# emif4 register map
Vendor: Texas Instruments
Peripheral module from a debugger description file (folder am335x).
Registers are 32-bit, access per field, no defined reset value unless marked. A register's access mark holds for its fields unless they carry their own. Offsets are as the file gives them; lines under a group give offsets from that group; [hi:lo] are bit positions; {n}, {i} and the like mark numbered series; 'fields as' and 'values as' point back to an identical list; <NAME> marks a mode.

## EMIF4D
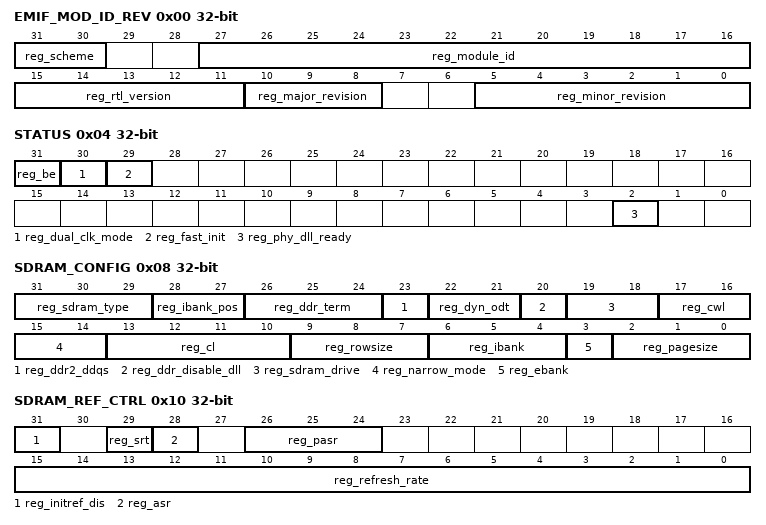
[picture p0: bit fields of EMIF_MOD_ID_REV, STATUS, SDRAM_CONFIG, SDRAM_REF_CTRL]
0x00 EMIF_MOD_ID_REV ro
  [31:30] reg_scheme — Used to distinguish between old and current schemes.
  [27:16] reg_module_id — EMIF module ID.
  [15:11] reg_rtl_version — RTL Version.
  [10:8] reg_major_revision — Major Revision.
  [5:0] reg_minor_revision — Minor Revision.
0x04 STATUS ro
  [31] reg_be — Big Endian. Reflects the value on the config_big_endian port that defines whether the EMIF is in big or little endian mode. 0 = Little endian. 1 = Big endian.
  [30] reg_dual_clk_mode — Dual Clock mode. Reflects the value on the config_dual_clk_mode port that defines whether the ocp_clk and m_clk are asynchronous. 0 = ocp_clk = m_clk. 1 = Asynchronous ocp_clk and m_clk.
  [29] reg_fast_init — Fast Init. Reflects the value on the config_fast_init port that defines whether the EMIF fast initialization mode has been enabled. 0 = Fast init disabled. 1 = Fast init enabled.
  [2] reg_phy_dll_ready — DDR PHY Ready. Reflects the value on the phy_ready port (active high) that defines whether the DDR PHY is ready for normal operation.
0x08 SDRAM_CONFIG rw
  [31:29] reg_sdram_type — SDRAM Type selection. Set to 0 for DDR1, set to 1 for LPDDR1, set to 2 for DDR2, set to 3 for DDR3. All other values are reserved.
  [28:27] reg_ibank_pos — Internal bank position. Set to 0 to assign internal bank address bits from lower OCP address bits, as shown in the tables for OCP Address to DDR2/3/mDDR Address Mapping. Set to 1, 2, or 3 to assign internal bank address bits from higher OCP address, as shown in the tables for OCP Address to DDR2/3/mDDR Address Mapping.
  [26:24] reg_ddr_term — DDR2 and DDR3 termination resistor value. Set to 0 to disable termination. For DDR2, set to 1 for 75 ohm, set to 2 for 150 ohm, and set to 3 for 50 ohm. For DDR3, set to 1 for RZQ/4, set to 2 for RZQ/2, set to 3 for RZQ/6, set to 4 for RZQ/12, and set to 5 for RZQ/8. All other values are reserved.
  [23] reg_ddr2_ddqs — DDR2 differential DQS enable. Set to 0 for single ended DQS. Set to 1 for differential DQS.
  [22:21] reg_dyn_odt — DDR3 Dynamic ODT. Set to 0 to turn off dynamic ODT. Set to 1 for RZQ/4 and set to 2 for RZQ/2. All other values are reserved.
  [20] reg_ddr_disable_dll — Disable DLL select. Set to 1 to disable DLL inside SDRAM.
  [19:18] reg_sdram_drive — SDRAM drive strength. For DDR1/DDR2, set to 0 for normal, and set to 1 for weak drive strength. For DDR3, set to 0 for RZQ/6 and set to 1 for RZQ/7. For LPDDR1, set to 0 for full, set to 1 for 1/2, set to 2 for 1/4, and set to 3 for 1/8 drive strength. All other values are reserved.
  [17:16] reg_cwl — DDR3 CAS Write latency. Value of 0, 1, 2, and 3 (CAS write latency of 5, 6, 7, and 8) are supported. Use the lowest value supported for best performance. All other values are reserved.
  [15:14] reg_narrow_mode — SDRAM data bus width. Set to 0 for 32-bit and set to 1 for 16-bit. All other values are reserved.
  [13:10] reg_cl — CAS Latency. The value of this field defines the CAS latency to be used when accessing connected SDRAM devices. Value of 2, 3, 5, and 6 (CAS latency of 2, 3, 1.5, and 2.5) are supported for DDR1. Value of 2, 3, 4, and 5 (CAS latency of 2, 3, 4, and 5) are supported for DDR2. Value of 2, 4, 6, 8, 10, 12, and 14 (CAS latency of 5, 6, 7, 8, 9, 10, and 11) are supported for DDR3. Value of 2 and 3 (CAS latency of 2 and 3) are supported for LPDDR1. All other values are reserved.
  [9:7] reg_rowsize — Row Size. Defines the number of row address bits of connected SDRAM devices. Set to 0 for 9 row bits, set to 1 for 10 row bits, set to 2 for 11 row bits, set to 3 for 12 row bits, set to 4 for 13 row bits, set to 5 for 14 row bits, set to 6 for 15 row bits, and set to 7 for 16 row bits. This field is only used when reg_ibank_pos field in SDRAM Config register is set to 1, 2, or 3, or reg_ebank_pos field in SDRAM Config_2 register is set to 1.
  [6:4] reg_ibank — Internal Bank setup. Defines number of banks inside connected SDRAM devices. Set to 0 for 1 bank, set to 1 for 2 banks, set to 2 for 4 banks, and set to 3 for 8 banks. All other values are reserved.
  [3] reg_ebank — External chip select setup. Defines whether SDRAM accesses will use 1 or 2 chip select lines. Set to 0 to use pad_cs_o_n[0] only. All other values reserved.
  [2:0] reg_pagesize — Page Size. Defines the internal page size of connected SDRAM devices. Set to 0 for 256-word page (8 column bits), set to 1 for 512-word page (9 column bits), set to 2 for 1024-word page (10 column bits), and set to 3 for 2048-word page (11 column bits). All other values are reserved.
0x0C SDRAM_CONFIG_2
  [27] reg_ebank_pos rw — External bank position. Set to 0 to assign external bank address bits from lower OCP address, as shown in the tables for OCP Address to DDR2/3/mDDR Address Mapping. Set to 1 to assign external bank address bits from higher OCP address bits, as shown in the tables for OCP Address to DDR2/3/mDDR Address Mapping.
0x10 SDRAM_REF_CTRL
  [31] reg_initref_dis rw — Initialization and Refresh disable. When set to 1, EMIF will disable SDRAM initialization and refreshes, but will carry out SDRAM write/read transactions.
  [29] reg_srt rw — DDR3 Self Refresh temperature range. Set to 0 for normal operating temperature range and set to 1 for extended operating temperature range when the reg_asr field is set to 0. This bit must be set to 0 if the reg_asr field is set to 1. A write to this field will cause the EMIF to start the SDRAM initialization sequence.
  [28] reg_asr rw — DDR3 Auto Self Refresh enable. Set to 1 for auto Self Refresh enable. Set to 0 for manual Self Refresh reference indicated by the reg_srt field. A write to this field will cause the EMIF to start the SDRAM initialization sequence.
  [26:24] reg_pasr rw — Partial Array Self Refresh. These bits get loaded into the Extended Mode Register of an LPDDR1 or DDR3 during initialization. For LPDDR1, set to 0 for full array, set to 1 for 1/2 array, set to 2 for 1/4 array, set to 5 for 1/8 array, and set to 6 for 1/16 array to be refreshed. For DDR3, set to 0 for full array, set to 1 or 5 for 1/2 array, set to 2 or 6 for 1/4 array, set to 3 or 7 for 1/8 array, and set to 4 for 3/4 array to be refreshed. All other values are reserved. A write to this field will cause the EMIF to start the SDRAM initialization sequence.
  [15:0] reg_refresh_rate rw — Refresh Rate. Value in this field is used to define the rate at which connected SDRAM devices will be refreshed. SDRAM refresh rate = EMIF rate / reg_refresh_rate where EMIF rate is equal to m_clk rate. If reg_refresh_rate andlt (8*reg_t_rfc)+reg_t_rp+reg_t_rcd+20 then it will be loaded with (8*reg_t_rfc)+reg_t_rp+reg_t_rcd+20. This is done to avoid lock-up situations when illegal values are programmed.
0x14 SDRAM_REF_CTRL_SHDW
  [15:0] reg_refresh_rate_shdw rw — Shadow field for reg_refresh_rate. This field is loaded into reg_refresh_rate field in SDRAM Refresh Control register when SIdleAck is asserted. This register is not auto corrected when the value is invalid.
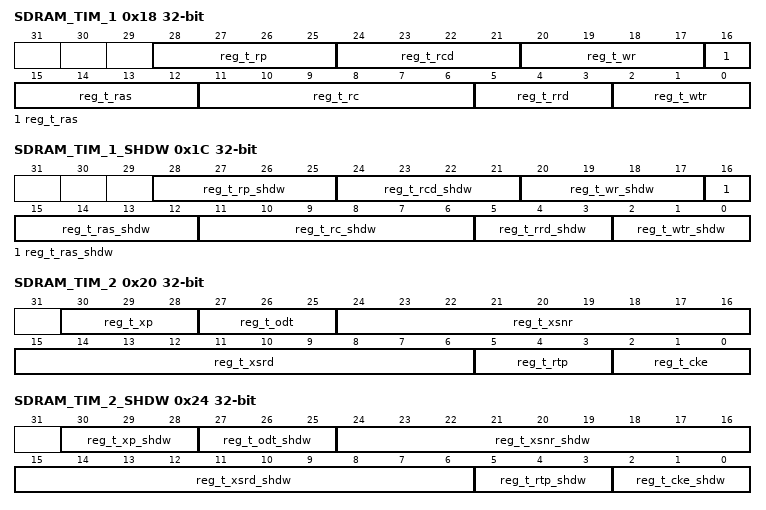
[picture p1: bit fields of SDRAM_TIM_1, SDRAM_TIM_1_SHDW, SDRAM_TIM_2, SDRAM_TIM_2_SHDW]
0x18 SDRAM_TIM_1
  [28:25] reg_t_rp rw — Minimum number of m_clk cycles from Precharge to Activate or Refresh, minus one.
  [24:21] reg_t_rcd rw — Minimum number of m_clk cycles from Activate to Read or Write, minus one.
  [20:17] reg_t_wr rw — Minimum number of m_clk cycles from last Write transfer to Pre-charge, minus one. The SDRAM initialization sequence will be started when the value of this field is changed from the previous value and the EMIF is in DDR2 mode.
  [16:12] reg_t_ras rw — Minimum number of m_clk cycles from Activate to Pre-charge, minus one. reg_t_ras >= reg_t_rcd.
  [11:6] reg_t_rc rw — Minimum number of m_clk cycles from Activate to Activate, minus one.
  [5:3] reg_t_rrd rw — Minimum number of m_clk cycles from Activate to Activate for a different bank, minus one. For an 8-bank DDR2, this field must be equal to ((((4*tRRD)+(2*tCK))/(4*tCK))-1).
  [2:0] reg_t_wtr rw — Minimum number of m_clk cycles from last Write to Read, minus one.
0x1C SDRAM_TIM_1_SHDW
  [28:25] reg_t_rp_shdw rw — Shadow field for reg_t_rp. This field is loaded into reg_t_rp field in SDRAM Timing 1 register when SIdleAck is asserted.
  [24:21] reg_t_rcd_shdw rw — Shadow field for reg_t_rcd. This field is loaded into reg_t_rcd field in SDRAM Timing 1 register when SIdleAck is asserted.
  [20:17] reg_t_wr_shdw rw — Shadow field for reg_t_wr. This field is loaded into reg_t_wr field in SDRAM Timing 1 register when SIdleAck is asserted. initialization sequence will be started when the value of this field is changed from the previous value and the EMIF is in DDR2 mode.
  [16:12] reg_t_ras_shdw rw — Shadow field for reg_t_ras. This field is loaded into reg_t_ras field in SDRAM Timing 1 register when SIdleAck is asserted.
  [11:6] reg_t_rc_shdw rw — Shadow field for reg_t_rc. This field is loaded into reg_t_rc field in SDRAM Timing 1 register when SIdleAck is asserted.
  [5:3] reg_t_rrd_shdw rw — Shadow field for reg_t_rrd. This field is loaded into reg_t_rrd field in SDRAM Timing 1 register when SIdleAck is asserted.
  [2:0] reg_t_wtr_shdw rw — Shadow field for reg_t_wtr. This field is loaded into reg_t_wtr field in SDRAM Timing 1 register when SIdleAck is asserted.
0x20 SDRAM_TIM_2
  [30:28] reg_t_xp rw — Minimum number of m_clk cycles from Powerdown exit to any command other than a Read command, minus one. For DDR2 and LPDDR1, this field must satisfy greater of tXP or tCKE.
  [27:25] reg_t_odt rw — Minimum number of m_clk cycles from ODT enable to write data driven for DDR2 and DDR3. reg_t_odt must be equal to tAOND.
  [24:16] reg_t_xsnr rw — Minimum number of m_clk cycles from Self-Refresh exit to any command other than a Read command, minus one.
  [15:6] reg_t_xsrd rw — Minimum number of m_clk cycles from Self-Refresh exit to a Read command, minus one.
  [5:3] reg_t_rtp rw — Minimum number of m_clk cycles from the last Read command to a Pre-charge command for DDR2, minus one.
  [2:0] reg_t_cke rw — Minimum number of m_clk cycles between pad_cke_o changes, minus one.
0x24 SDRAM_TIM_2_SHDW
  [30:28] reg_t_xp_shdw rw — Shadow field for reg_t_xp. This field is loaded into reg_t_xp field in SDRAM Timing 2 register when SIdleAck is asserted.
  [27:25] reg_t_odt_shdw rw — Shadow field for reg_t_odt. This field is loaded into reg_t_odt field in SDRAM Timing 2 register when SIdleAck is asserted.
  [24:16] reg_t_xsnr_shdw rw — Shadow field for reg_t_xsnr. This field is loaded into reg_t_xsnr field in SDRAM Timing 2 register when SIdleAck is asserted.
  [15:6] reg_t_xsrd_shdw rw — Shadow field for reg_t_xsrd. This field is loaded into reg_t_xsrd field in SDRAM Timing 2 register when SIdleAck is asserted.
  [5:3] reg_t_rtp_shdw rw — Shadow field for reg_t_rtp. This field is loaded into reg_t_rtp field in SDRAM Timing 2 register when SIdleAck is asserted.
  [2:0] reg_t_cke_shdw rw — Shadow field for reg_t_cke. This field is loaded into reg_t_cke field in SDRAM Timing 2 register when SIdleAck is asserted.
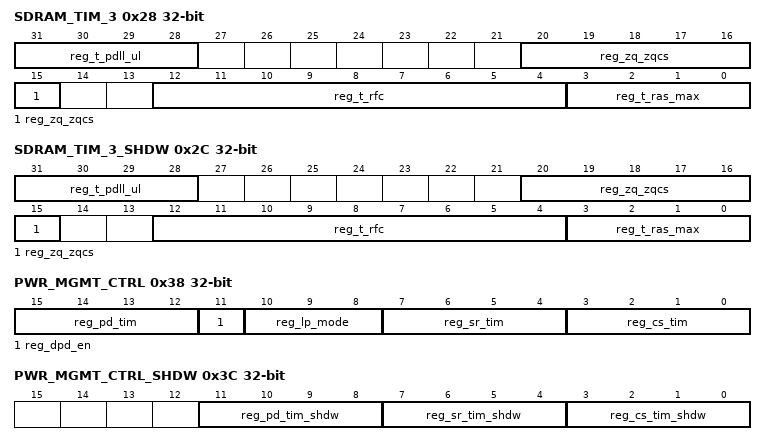
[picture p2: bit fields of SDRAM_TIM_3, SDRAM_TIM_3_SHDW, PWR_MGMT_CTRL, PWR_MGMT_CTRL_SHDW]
0x28 SDRAM_TIM_3
  [31:28] reg_t_pdll_ul rw — Minimum number of DDR clock cycles for PHY DLL to unlock. A value of N will be equal to N x 128 clocks.
  [20:15] reg_zq_zqcs rw — Number of DDR clock clock cycles for a ZQCS command, minus one.
  [12:4] reg_t_rfc rw — Minimum number of DDR clock cycles from Refresh or Load Mode to Refresh or Activate, minus one.
  [3:0] reg_t_ras_max rw — Maximum number of reg_refresh_rate intervals from Activate to Precharge command. This field must be equal to ((tRASmax / tREFI)-1) rounded down to the next lower integer. This field is only applicable for mDDR. This field must be programmed to 0xF for other SDRAM types.
0x2C SDRAM_TIM_3_SHDW
  fields as SDRAM_TIM_3
0x38 PWR_MGMT_CTRL
  [15:12] reg_pd_tim rw — Power Mangement timer for Power-Down. The EMIF will put the external SDRAM in Power-Down mode after the EMIF is idle for these number of m_clk cycles and if reg_lp_mode field is set to 4. Set to 0 to immediately enter Power-Down mode. Set to 1 for 16 clocks. Set to 2 for 32 clocks. Set to 3 for 64 clocks. Set to 4 for 128 clocks. Set to 5 for 256 clocks. Set to 6 for 512 clocks. Set to 7 for 1024 clocks. Set to 8 for 2048 clocks. Set to 9 for 4096 clocks. Set to 10 for 8192 clocks. Set to 11 for 16384 clocks. Set to 12 for 32768 clocks. Set to 13 for 65536 clocks. Set to 14 for 131072 clocks. Set to 15 for 262144 clocks. Note: After updating this field, at least one dummy read access to SDRAM is required for the new value to take affect.
  [11] reg_dpd_en rw — Deep Power Down enable. Set to 0 for normal operation. Set to 1 to enter deep power down mode. This mode will override the reg_lp_mode field setting.
  [10:8] reg_lp_mode rw — Automatic Power Management enable. Set to 1 for Clock Stop, set to 2 for Self Refresh, and set to 4 for Power-Down. All other values will disable automatic power management.
  [7:4] reg_sr_tim rw — Power Mangement timer for Self Refresh. The EMIF will put the external SDRAM in Self Refresh mode after the EMIF is idle for these number of m_clk cycles and if reg_lp_mode field is set to 2. Set to 0 to immediately enter Self Refresh mode. Set to 1 for 16 clocks. Set to 2 for 32 clocks. Set to 3 for 64 clocks. Set to 4 for 128 clocks. Set to 5 for 256 clocks. Set to 6 for 512 clocks. Set to 7 for 1024 clocks. Set to 8 for 2048 clocks. Set to 9 for 4096 clocks. Set to 10 for 8192 clocks. Set to 11 for 16384 clocks. Set to 12 for 32768 clocks. Set to 13 for 65536 clocks. Set to 14 for 131072 clocks. Set to 15 for 262144 clocks. Note: After updating this field, at least one dummy read access to SDRAM is required for the new value to take affect.
  [3:0] reg_cs_tim rw — Power Mangement timer for Clock Stop. The EMIF will put the external SDRAM in Clock Stop mode after the EMIF is idle for these number of m_clk cycles and if reg_lp_mode field is set to 1. Set to 0 to immediately enter Clock Stop mode. Set to 1 for 16 clocks. Set to 2 for 32 clocks. Set to 3 for 64 clocks. Set to 4 for 128 clocks. Set to 5 for 256 clocks. Set to 6 for 512 clocks. Set to 7 for 1024 clocks. Set to 8 for 2048 clocks. Set to 9 for 4096 clocks. Set to 10 for 8192 clocks. Set to 11 for 16384 clocks. Set to 12 for 32768 clocks. Set to 13 for 65536 clocks. Set to 14 for 131072 clocks. Set to 15 for 262144 clocks. Note: After updating this field, at least one dummy read access to SDRAM is required for the new value to take affect.
0x3C PWR_MGMT_CTRL_SHDW
  [11:8] reg_pd_tim_shdw rw — Shadow field for reg_pd_tim. This field is loaded into reg_pd_tim field in Power Management Control register when SIdleAck is asserted.
  [7:4] reg_sr_tim_shdw rw — Shadow field for reg_sr_tim. This field is loaded into reg_sr_tim field in Power Management Control register when SIdleAck is asserted.
  [3:0] reg_cs_tim_shdw rw — Shadow field for reg_cs_tim. This field is loaded into reg_cs_tim field in Power Management Control register when SIdleAck is asserted.
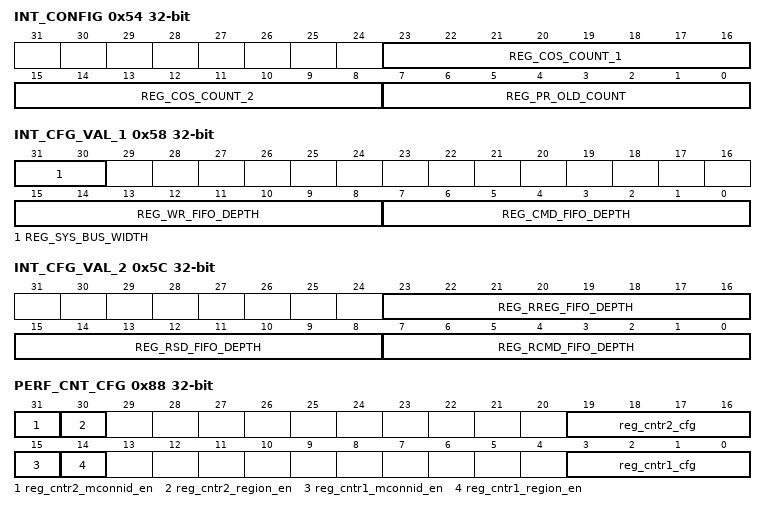
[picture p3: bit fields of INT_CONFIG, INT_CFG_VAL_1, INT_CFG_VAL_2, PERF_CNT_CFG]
0x54 INT_CONFIG access not given
  [23:16] REG_COS_COUNT_1 rw — Priority Raise Counter for class of service 1. Number of m_clk cycles after which the EMIF momentarily raises the priority of the class of service 1 commands in the Command FIFO. A value of N will be equal to N x 16 clocks.
  [15:8] REG_COS_COUNT_2 rw — Priority Raise Counter for class of service 2. Number of m_clk cycles after which the EMIF momentarily raises the priority of the class of service 2 commands in the Command FIFO. A value of N will be equal to N x 16 clocks.
  [7:0] REG_PR_OLD_COUNT — Priority Raise Old Counter. Number of m_clk cycles after which the EMIF momentarily raises the priority of the oldest command in the OCP Command FIFO. A value of N will be equal to N x 16 clocks.
0x58 INT_CFG_VAL_1 ro
  [31:30] REG_SYS_BUS_WIDTH — L3 OCP data bus width for a particular configuration. 0 = 32 bit wide. 1 = 64 bit wide. 2 = 128 bit wide. 3 = 256 bit wide.
  [15:8] REG_WR_FIFO_DEPTH — Write Data FIFO depth for a particular configuration.
  [7:0] REG_CMD_FIFO_DEPTH — Command FIFO depth for a particular configuration.
0x5C INT_CFG_VAL_2 ro
  [23:16] REG_RREG_FIFO_DEPTH — Register Read Data FIFO depth for a particular configuration.
  [15:8] REG_RSD_FIFO_DEPTH — SDRAM Read Data FIFO depth for a particular configuration.
  [7:0] REG_RCMD_FIFO_DEPTH — Read Command FIFO depth for a particular configuration.
0x80 PERF_CNT_1 ro
  [31:0] reg_counter1 — 32-bit counter that can be configured as specified in the Performance Counter Config Register and Performance Counter Master Region Select Register.
0x84 PERF_CNT_2 ro
  [31:0] reg_counter2 — 32-bit counter that can be configured as specified in the Performance Counter Config Register and Performance Counter Master Region Select Register.
0x88 PERF_CNT_CFG
  [31] reg_cntr2_mconnid_en rw — MConnID filter enable for Performance Counter 2 register.
  [30] reg_cntr2_region_en rw — Chip Select filter enable for Performance Counter 2 register.
  [19:16] reg_cntr2_cfg rw — Filter configuration for Performance Counter 2. Refer to table for details.
  [15] reg_cntr1_mconnid_en rw — MConnID filter enable for Performance Counter 1 register.
  [14] reg_cntr1_region_en rw — Chip Select filter enable for Performance Counter 1 register.
  [3:0] reg_cntr1_cfg rw — Filter configuration for Performance Counter 1. Refer to table for details.
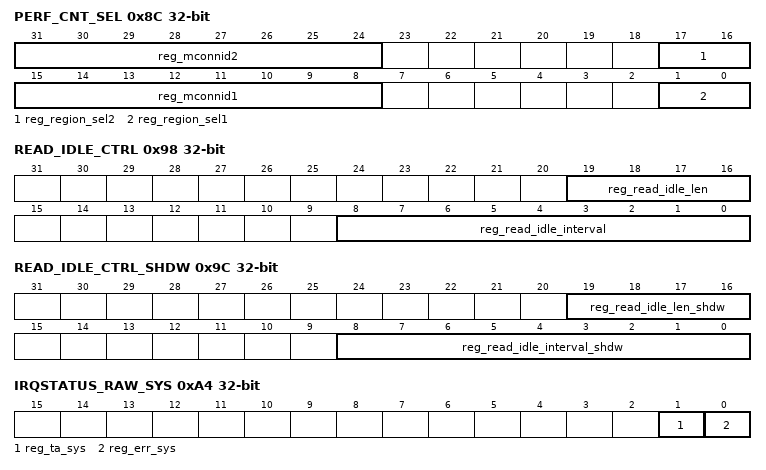
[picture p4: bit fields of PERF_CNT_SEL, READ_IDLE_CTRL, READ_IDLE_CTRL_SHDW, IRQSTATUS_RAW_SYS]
0x8C PERF_CNT_SEL
  [31:24] reg_mconnid2 rw — MConnID for Performance Counter 2 register.
  [17:16] reg_region_sel2 rw — MAddrSpace for Performance Counter 2 register.
  [15:8] reg_mconnid1 rw — MConnID for Performance Counter 1 register.
  [1:0] reg_region_sel1 rw — MAddrSpace for Performance Counter 1 register.
0x90 PERF_CNT_TIM ro
  [31:0] reg_total_time — 32-bit counter that continuously counts number for m_clk cycles elapsed after EMIF is brought out of reset.
0x98 READ_IDLE_CTRL
  [19:16] reg_read_idle_len rw — The Read Idle Length field determines the minimum size (reg_read_idle_len-1 clock cycles) of Read Idle window for the read idle detection as well as the force read idle time.
  [8:0] reg_read_idle_interval rw — The Read Idle Interval field determines the maximum interval ((reg_read_idle_interval-1)*64 clock cycles) between read idle detections or force. A value of zero disables the read idle function.
0x9C READ_IDLE_CTRL_SHDW
  [19:16] reg_read_idle_len_shdw rw — Shadow field for reg_read_idle_len. This field is loaded into reg_read_idle_len field in Read Idle Control register when SIdleAck is asserted
  [8:0] reg_read_idle_interval_shdw rw — Shadow field for reg_read_idle_interval. This field is loaded into reg_read_idle_interval field in Read Idle Control register when SIdleAck is asserted.
0xA4 IRQSTATUS_RAW_SYS
  [1] reg_ta_sys rw — Raw status of system OCP interrupt. Write 1 to set the (raw) status, mostly for debug. Writing a 0 has no effect.
  [0] reg_err_sys rw — Raw status of system OCP interrupt. Write 1 to set the (raw) status, mostly for debug. Writing a 0 has no effect.
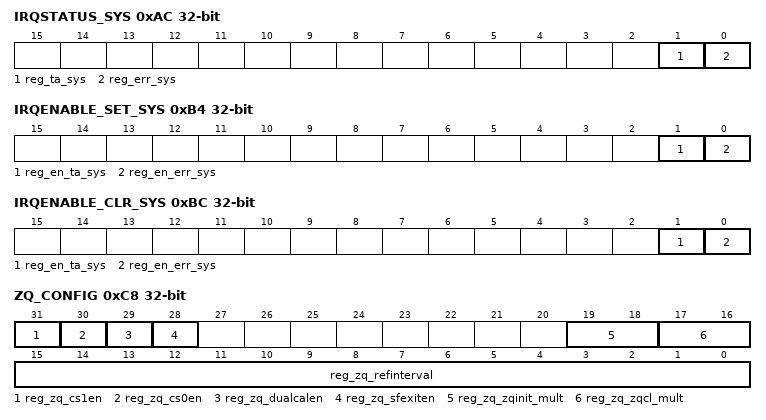
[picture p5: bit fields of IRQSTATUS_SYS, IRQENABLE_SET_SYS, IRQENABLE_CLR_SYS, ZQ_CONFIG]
0xAC IRQSTATUS_SYS
  [1] reg_ta_sys rw — Enabled status of system OCP interrupt. Write 1 to clear the status after interrupt has been serviced (raw status gets cleared, i.e. even if not enabled). Writing a 0 has no effect.
  [0] reg_err_sys rw — Enabled status of system OCP interrupt. Write 1 to clear the status after interrupt has been serviced (raw status gets cleared, i.e. even if not enabled). Writing a 0 has no effect.
0xB4 IRQENABLE_SET_SYS
  [1] reg_en_ta_sys rw — Enable set for system OCP interrupt. Writing a 1 will enable the interrupt, and set this bit as well as the corresponding Interrupt Enable Clear Register. Writing a 0 has no effect.
  [0] reg_en_err_sys rw — Enable set for system OCP interrupt. Writing a 1 will enable the interrupt, and set this bit as well as the corresponding Interrupt Enable Clear Register. Writing a 0 has no effect.
0xBC IRQENABLE_CLR_SYS
  [1] reg_en_ta_sys rw — Enable clear for system OCP interrupt. Writing a 1 will disable the interrupt, and clear this bit as well as the corresponding Interrupt Enable Set Register. Writing a 0 has no effect.
  [0] reg_en_err_sys rw — Enable clear for system OCP interrupt. Writing a 1 will disable the interrupt, and clear this bit as well as the corresponding Interrupt Enable Set Register. Writing a 0 has no effect.
0xC8 ZQ_CONFIG
  [31] reg_zq_cs1en rw — Writing a 1 enables ZQ calibration for CS1.
  [30] reg_zq_cs0en rw — Writing a 1 enables ZQ calibration for CS0.
  [29] reg_zq_dualcalen rw — ZQ Dual Calibration enable. Allows both ranks to be ZQ calibrated simultaneously. Setting this bit requires both chip selects to have a seerate calibration resistor per device.
  [28] reg_zq_sfexiten rw — ZQCL on Self Refresh, Active Power-Down, and Precharge Power-Down exit enable. Writing a 1 enables the issuing of ZQCL on Self-Refresh, Active Power-Down, and Precharge Power-Down exit.
  [19:18] reg_zq_zqinit_mult rw — Indicates the number of ZQCL intervals that make up a ZQINIT interval, minus one.
  [17:16] reg_zq_zqcl_mult rw — Indicates the number of ZQCS intervals that make up a ZQCL interval, minus one. ZQCS interval is defined by reg_zq_zqcs in SDRAM Timing 3 Register.
  [15:0] reg_zq_refinterval rw — Number of refresh periods between ZQCS commans. This field supports between one refresh period to 256 ms between ZQCS calibration commands. Refresh period is defined by reg_refresh_rate in SDRAM Refresh Control register.
0xD4 RDWR_LVL_RMP_WIN ro
  [12:0] REG_RDWRLVLINC_RMP_WIN — Incremental leveling ramp window in number of refresh periods. The value programmed is minus one the required value. Refresh period is defined by reg_refresh_rate in SDRAM Refresh Control register.
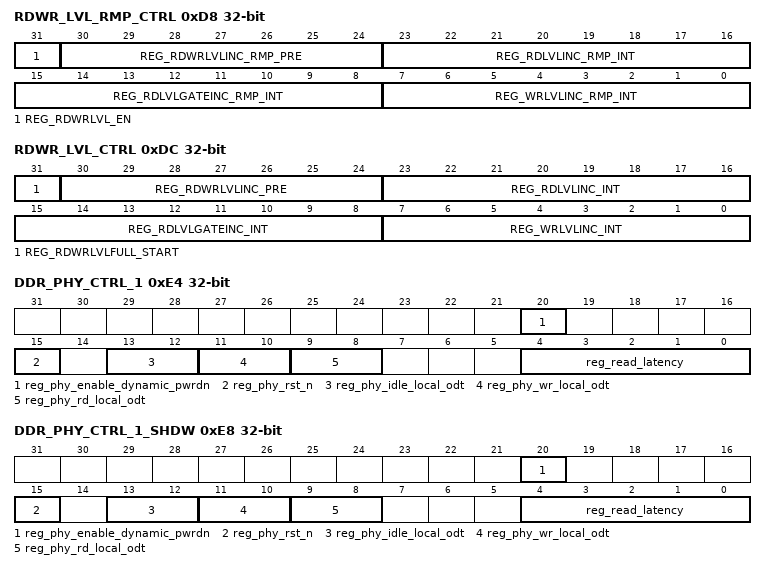
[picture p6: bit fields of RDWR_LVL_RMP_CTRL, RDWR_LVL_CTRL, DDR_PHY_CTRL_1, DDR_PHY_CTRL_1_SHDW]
0xD8 RDWR_LVL_RMP_CTRL access not given
  [31] REG_RDWRLVL_EN rw — Read-Write Leveling enable. Set 1 to enable leveling. Set 0 to disable leveling.
  [30:24] REG_RDWRLVLINC_RMP_PRE — Incremental leveling pre-scalar in number of refresh periods during ramp window. The value programmed is minus one the required value. Refresh period is defined by reg_refresh_rate in SDRAM Refresh Control register.
  [23:16] REG_RDLVLINC_RMP_INT rw — Incremental read data eye training interval during ramp window. Number of reg_rdwrlvlinc_rmp_pre intervals between incremental read data eye training. A value of 0 will disable incremental read data eye training during ramp window.
  [15:8] REG_RDLVLGATEINC_RMP_INT rw — Incremental read DQS gate training interval during ramp window. Number of reg_rdwrlvlinc_rmp_pre intervals between incremental read DQS gate training. A value of 0 will disable incremental read DQS gate training during ramp window.
  [7:0] REG_WRLVLINC_RMP_INT — Incremental write leveling interval during ramp window. Number of reg_rdwrlvlinc_rmp_pre intervals between incremental write leveling. A value of 0 will disable incremental write leveling during ramp window.
0xDC RDWR_LVL_CTRL access not given — Read-Write Leveling Control Register
  [31] REG_RDWRLVLFULL_START rw — Full leveling trigger. Writing a 1 to this field triggers full read and write leveling. This bit will self-clear to 0.
  [30:24] REG_RDWRLVLINC_PRE — Incremental leveling pre-scalar in number of refresh periods. The value programmed is minus one the required value. Refresh period is defined by reg_refresh_rate in SDRAM Refresh Control register.
  [23:16] REG_RDLVLINC_INT rw — Incremental read data eye training interval. Number of reg_rdwrlvlinc_pre intervals between incremental read data eye training. A value of 0 will disable incremental read data eye training.
  [15:8] REG_RDLVLGATEINC_INT rw — Incremental read DQS gate training interval. Number of reg_rdwrlvlinc_pre intervals between incremental read DQS gate training. A value of 0 will disable incremental read DQS gate training.
  [7:0] REG_WRLVLINC_INT rw — Incremental write leveling interval. Number of reg_rdwrlvlinc_pre intervals between incremental write leveling. A value of 0 will disable incremental write leveling.
0xE4 DDR_PHY_CTRL_1 rw — A write to the DDR PHY Control 1 register must be followed by a write to the SDRAM_CONFIG register to ensure that the control update/acknowledge protocol is performed on the DID. If CAS latency = 5, the minimum read latency = 5 + 2 = 7 and reg_read_latency must be programmed as 7 - 1 = 6. The maximum read latency = 5 + 7 = 12 and reg_read_latency must be programmed as 12 - 1 = 11.
  [20] reg_phy_enable_dynamic_pwrdn — 0 = Power down PHY data macros. 1 = Enable power to PHY data macros.
  [15] reg_phy_rst_n — Writing a 1 to this bit will hold the PHY macros in reset. Writing a 0 will bring PHY macros out of reset.
  [13:12] reg_phy_idle_local_odt — Value to drive on the 2-bit local_odt PHY outputs when reg_phy_dynamic_pwrdn_enable is asserted and a read is not in progress and reg_phy_dynamic_pwrdn_enable. Typically this is the value required to disable termination (00) to save power when idle.
  [11:10] reg_phy_wr_local_odt — This bit controls the value assigned to the reg_phy_wr_local_odt input on the data macros. Always set to 00.
  [9:8] reg_phy_rd_local_odt — Value to drive on the 2-bit local_odt PHY outputs when output enable is not asserted and a read is in progress (where ‘in progress’ is defined as after a read command is issued and until all read data has been returned all the way to the controller.) Typically this is set to the value required to enable termination at the desired strength for read usage. 00 = ODT off. 01 = ODT off. 10 = Full thevenin load. 11 = Half thevenin load.
  [4:0] reg_read_latency — This field defines the latency for read data from DDR SDRAM in number of DDR clock cycles. The value applied should be equal to the required value minus one. The maximum read latency supported by the DDR PHY is equal to CAS latency plus 7 clock cycles. The minimum read latency must be equal to CAS latency plus 2 clock cycle.
0xE8 DDR_PHY_CTRL_1_SHDW rw — A write to the DDR PHY Control 1 register must be followed by a write to the SDRAM_CONFIG register to ensure that the control update/acknowledge protocol is performed on the DID. If CAS latency = 5, the minimum read latency = 5 + 2 = 7 and reg_read_latency must be programmed as 7 - 1 = 6. The maximum read latency = 5 + 7 = 12 and reg_read_latency must be programmed as 12 - 1 = 11.
  fields as DDR_PHY_CTRL_1
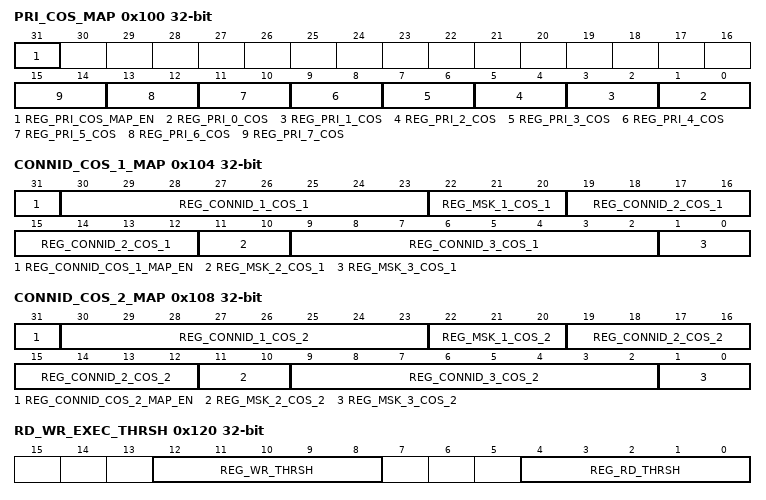
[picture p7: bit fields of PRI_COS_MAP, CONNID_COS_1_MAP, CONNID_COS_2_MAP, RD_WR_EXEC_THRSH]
0x100 PRI_COS_MAP
  [31] REG_PRI_COS_MAP_EN rw — Set 1 to enable priority to class of service mapping. Set 0 to disable mapping.
  [2n+1:2n] REG_PRI_{n}_COS rw (n=0..7) — Class of service for commands with priority of {n}. Value can be 1 or 2. Setting a value of 0 or 3 will not assign any class of service.
0x104 CONNID_COS_1_MAP rw
  [31] REG_CONNID_COS_1_MAP_EN — Set 1 to enable connection ID to class of service 1 mapping. Set 0 to disable mapping.
  [30:23] REG_CONNID_1_COS_1 — Connection ID value 1 for class of service 1.
  [22:20] REG_MSK_1_COS_1 — Mask for connection ID value 1 for class of service 1. 0 = disable masking. 1 = mask connection ID bit 0. 2 = mask connection ID bits 1:0. 3 = mask connection ID bits 2:0. 4 = mask connection ID bits 3:0. 5 = mask connection ID bits 4:0. 6 = mask connection ID bits 5:0. 7 = mask connection ID bits 6:0.
  [19:12] REG_CONNID_2_COS_1 — Connection ID value 2 for class of service 1.
  [11:10] REG_MSK_2_COS_1 — Mask for connection ID value 2 for class of service 1. 0 = disable masking. 1 = mask connection ID bit 0. 2 = mask connection ID bits 1:0. 3 = mask connection ID bits 2:0.
  [9:2] REG_CONNID_3_COS_1 — Connection ID value 3 for class of service 1.
  [1:0] REG_MSK_3_COS_1 — Mask for connection ID. Value 3 for class of service 1. 0 = disable masking. 1 = mask connection ID bit 0. 2 = mask connection ID bits 1:0. 3 = mask connection ID bits 2:0.
0x108 CONNID_COS_2_MAP rw
  [31] REG_CONNID_COS_2_MAP_EN — Set 1 to enable connection ID to class of service 2 mapping. Set 0 to disable mapping.
  [30:23] REG_CONNID_1_COS_2 — Connection ID value 1 for class of service 2.
  [22:20] REG_MSK_1_COS_2 — Mask for connection ID. Value 1 for class of service 2. 0 = disable masking. 1 = mask connection ID bit 0. 2= mask connection ID bits 1:0. 3= mask connection ID bits 2:0. 4 = mask connection ID bits 3:0. 5 = mask connection ID bits 4:0. 6 = mask connection ID bits 5:0. 7 = mask connection ID bits 6:0.
  [19:12] REG_CONNID_2_COS_2 — Connection ID value 2 for class of service 2.
  [11:10] REG_MSK_2_COS_2 — Mask for connection ID. Value 2 for class of service 2. 0 = disable masking. 1 = mask connection ID bit 0. 2 = mask connection ID bits 1:0. 3 = mask connection ID bits 2:0.
  [9:2] REG_CONNID_3_COS_2 — Connection ID value 3 for class of service 2.
  [1:0] REG_MSK_3_COS_2 — Mask for connection ID. Value 3 for class of service 2. 0 = disable masking. 1 = mask connection ID bit 0. 2 = mask connection ID bits 1:0. 3 = mask connection ID bits 2:0.
0x120 RD_WR_EXEC_THRSH
  [12:8] REG_WR_THRSH rw — Write Threshold. Number of SDRAM write bursts after which the EMIF arbitration will switch to executing read commands. The value programmed is always minus one the required number.
  [4:0] REG_RD_THRSH rw — Read Threshold. Number of SDRAM read bursts after which the EMIF arbitration will switch to executing write commands. The value programmed is always minus one the required number.
